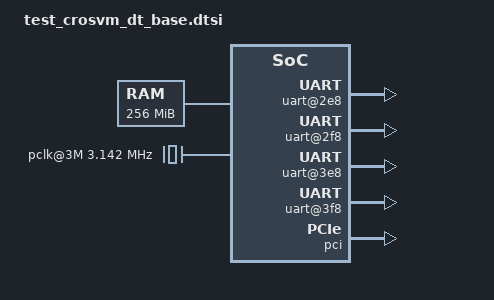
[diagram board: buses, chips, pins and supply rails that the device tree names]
/dts-v1/;

// This is generated manually by removing unassigned pvIOMMU nodes
// from patched platform.dts.

/ {
	interrupt-parent = <0x01>;
	compatible = "linux,dummy-virt";
	#address-cells = <0x02>;
	#size-cells = <0x02>;

	chosen {
		bootargs = "panic=-1 crashkernel=31M";
		linux,initrd-end = <0x811d6cb8>;
		linux,initrd-start = <0x81000000>;
		stdout-path = "/uart@3f8";
		1,pci-probe-only = <0x01>;
		kaslr-seed = <0x00 0x00>;
		avf,strict-boot;
		avf,new-instance;
	};

	memory {
		device_type = "memory";
		reg = <0x00 0x80000000 0x00 0x10000000>;
	};

	reserved-memory {
		#address-cells = <0x02>;
		#size-cells = <0x02>;
		ranges;

		restricted_dma_reserved {
			compatible = "restricted-dma-pool";
			size = <0x00 0xe00000>;
			alignment = <0x00 0x1000>;
			phandle = <0x02>;
		};

		dice {
			compatible = "google,open-dice";
			no-map;
			reg = <0x00 0x7fe25000 0x00 0x1000>;
		};
	};

	cpus {
		#address-cells = <0x01>;
		#size-cells = <0x00>;

		cpu@0 {
			device_type = "cpu";
			compatible = "arm,armv8";
			enable-method = "psci";
			reg = <0x00>;
		};
	};

	intc {
		compatible = "arm,gic-v3";
		#address-cells = <0x02>;
		#size-cells = <0x02>;
		#interrupt-cells = <0x03>;
		interrupt-controller;
		reg = <0x00 0x3fff0000 0x00 0x10000 0x00 0x3ffd0000 0x00 0x20000>;
		phandle = <0x01>;
	};

	timer {
		compatible = "arm,armv8-timer";
		always-on;
		interrupts = <0x01 0x0d 0x108 0x01 0x0e 0x108 0x01 0x0b 0x108 0x01 0x0a 0x108>;
	};

	uart@2e8 {
		compatible = "ns16550a";
		reg = <0x00 0x2e8 0x00 0x08>;
		clock-frequency = <0x1c2000>;
		interrupts = <0x00 0x02 0x01>;
	};

	uart@2f8 {
		compatible = "ns16550a";
		reg = <0x00 0x2f8 0x00 0x08>;
		clock-frequency = <0x1c2000>;
		interrupts = <0x00 0x02 0x01>;
	};

	uart@3e8 {
		compatible = "ns16550a";
		reg = <0x00 0x3e8 0x00 0x08>;
		clock-frequency = <0x1c2000>;
		interrupts = <0x00 0x00 0x01>;
	};

	uart@3f8 {
		compatible = "ns16550a";
		reg = <0x00 0x3f8 0x00 0x08>;
		clock-frequency = <0x1c2000>;
		interrupts = <0x00 0x00 0x01>;
	};

	psci {
		compatible = "arm,psci-1.0";
		method = "hvc";
	};

	pci {
		compatible = "pci-host-cam-generic";
		device_type = "pci";
		#address-cells = <0x03>;
		#size-cells = <0x02>;
		#interrupt-cells = <0x01>;
		dma-coherent;
		memory-region = <0x02>;
		ranges = <0x3000000 0x00 0x2000000 0x00 0x2000000 0x00 0x2000000 0x3000000 0x00 0x90800000 0x00 0x90800000 0xff 0x6f800000>;
		bus-range = <0x00 0x00>;
		reg = <0x00 0x10000 0x00 0x1000000>;
		interrupt-map = <0x800 0x00 0x00 0x01 0x01 0x00 0x00 0x00 0x04 0x04 0x1000 0x00 0x00 0x01 0x01 0x00 0x00 0x00 0x05 0x04 0x1800 0x00 0x00 0x01 0x01 0x00 0x00 0x00 0x06 0x04 0x2000 0x00 0x00 0x01 0x01 0x00 0x00 0x00 0x07 0x04 0x2800 0x00 0x00 0x01 0x01 0x00 0x00 0x00 0x08 0x04 0x3000 0x00 0x00 0x01 0x01 0x00 0x00 0x00 0x09 0x04 0x3800 0x00 0x00 0x01 0x01 0x00 0x00 0x00 0x0a 0x04 0x4000 0x00 0x00 0x01 0x01 0x00 0x00 0x00 0x0b 0x04 0x4800 0x00 0x00 0x01 0x01 0x00 0x00 0x00 0x0c 0x04>;
		interrupt-map-mask = <0xf800 0x00 0x00 0x07 0xf800 0x00 0x00 0x07 0xf800 0x00 0x00 0x07 0xf800 0x00 0x00 0x07 0xf800 0x00 0x00 0x07 0xf800 0x00 0x00 0x07 0xf800 0x00 0x00 0x07 0xf800 0x00 0x00 0x07 0xf800 0x00 0x00 0x07>;
	};

	pclk@3M {
		compatible = "fixed-clock";
		clock-frequency = <0x2fefd8>;
		#clock-cells = <0x00>;
		phandle = <0x03>;
	};

	rtc@2000 {
		compatible = "arm,primecell";
		arm,primecell-periphid = <0x41030>;
		reg = <0x00 0x2000 0x00 0x1000>;
		interrupts = <0x00 0x01 0x04>;
		clock-names = "apb_pclk";
		clocks = <0x03>;
	};

	vmwdt@3000 {
		compatible = "qemu,vcpu-stall-detector";
		reg = <0x00 0x3000 0x00 0x1000>;
		clock-frequency = <0x0a>;
		timeout-sec = <0x08>;
		interrupts = <0x01 0xf 0x101>; // <GIC_PPI 0xf IRQ_TYPE_EDGE_RISING>
	};

	__symbols__ {
		swiotlb = "/reserved-memory/restricted_dma_reserved";
		intc = "/intc";
		clk = "/pclk@3M";
	};
};
